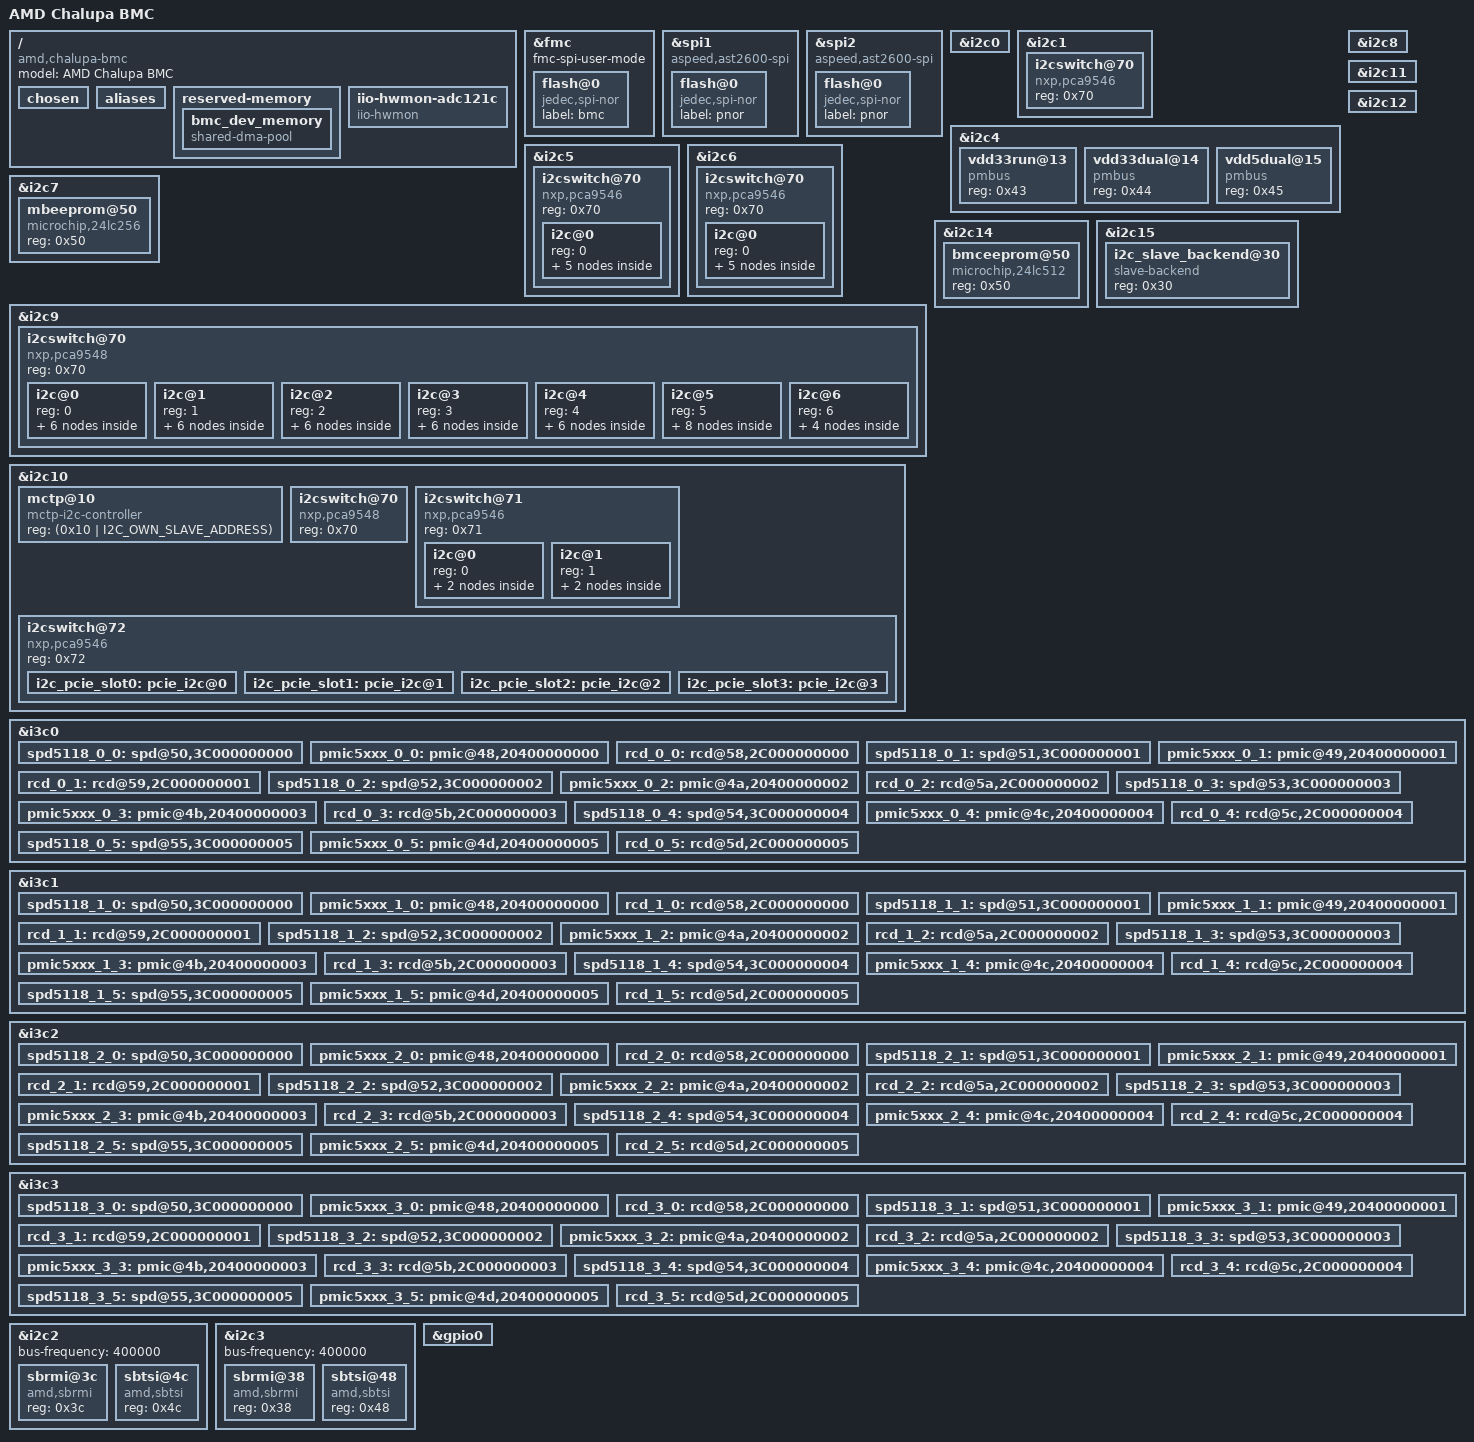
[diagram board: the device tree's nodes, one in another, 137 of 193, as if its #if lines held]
// SPDX-License-Identifier: GPL-2.0
// Copyright (c) 2022 AMD Inc.
// Author: Mohsen Dolaty <mohsen.dolaty@amd.com>
// Author: Supreeth Venkatesh <supreeth.venkatesh@amd.com>

/dts-v1/;
#include "ast2600-amd-bmc-common.dtsi"
#include <dt-bindings/i2c/i2c.h>
#include <dt-bindings/i3c/i3c.h>

/ {
	model = "AMD Chalupa BMC";
	compatible = "amd,chalupa-bmc", "aspeed,ast2600";


	chosen {
		stdout-path = &uart5;
		bootargs = "console=ttyS4,115200 earlycon vmalloc=512MB";
	};
	aliases {
	
		i2c180 = &i2c_pcie_slot0;
		i2c181 = &i2c_pcie_slot1;
		i2c182 = &i2c_pcie_slot2;
		i2c183 = &i2c_pcie_slot3;
	};

	reserved-memory {
		#address-cells = <1>;
		#size-cells = <1>;
		ranges;

        bmc_dev_memory: bmc_dev_memory {
            size = <0x00100000>;
            alignment = <0x00100000>;
            compatible = "shared-dma-pool";
            no-map;
        };
	};

	iio-hwmon-adc121c {
		compatible = "iio-hwmon";
		oemname0 = "FPGA_VDD_CORE";
		oemname1 = "FPGA_VDD_18";
		oemname2 = "FPGA_VDD_33";
		oemname3 = "LOM_VDD_33";
		oemname4 = "LOM_VDD_12";
		oemname5 = "VDD_12_DUAL";
		io-channels = <&adc0 0>, <&adc1 0>, <&adc2 0>, <&adc3 0>,
					<&adc4 0>, <&adc5 0>;
	};
};


&fmc {
	status = "okay";
	fmc-spi-user-mode;
	flash@0 {
		compatible = "jedec,spi-nor";
		status = "okay";
		label = "bmc";
		//spi-tx-bus-width = <4>;
		//spi-rx-bus-width = <4>;
		#include "openbmc-flash-layout-128.dtsi"
	};
};

&spi1 {
	status = "okay";
	pinctrl-names = "default";
	pinctrl-0 = <&pinctrl_spi1_default &pinctrl_qspi1_default>;
	fmc-spi-user-mode;
	compatible = "aspeed,ast2600-spi";

	flash@0 {
		compatible = "jedec,spi-nor";
		label = "pnor";
		status = "okay";
	};

};

&spi2 {
	status = "okay";
	pinctrl-names = "default";
	pinctrl-0 = <&pinctrl_spi2_default &pinctrl_qspi2_default>;
	fmc-spi-user-mode;
	compatible = "aspeed,ast2600-spi";

	flash@0 {
		compatible = "jedec,spi-nor";
		label = "pnor";
		status = "okay";
	};

};

// I2C configs
&i2c0 {
	//Net name i2c9 (SCM_I2C9)- MB FPGA slave
	status = "okay";
};

&i2c1 {
	//Net name i2c12 (SCM_I2C12) - LCD at 50KHz
	// Connected to TCA9546A and to LCD HDR
	status = "okay";
#ifdef OPENBMC_LCD_DRIVER
	i2cswitch@70 {
		compatible = "nxp,pca9546";
		reg = <0x70>;
		//<TBD> Define LCD details here
	};
#endif //OPENBMC_LCD_DRIVER
};

&i2c4 {
	// Net name i2c1 (SCM_I2C1)
	status = "okay";
	vdd33run@13 {
		//VDD_33_RUN VRM
		compatible = "pmbus";
		reg = <0x43>;
	};
	vdd33dual@14 {
		//VDD_33_DUAL VRM
		compatible = "pmbus";
		reg = <0x44>;
	};
	vdd5dual@15 {
		//VDD_5_DUAL VRM
		compatible = "pmbus";
		reg = <0x45>;
	};
};

// BMC Chalupa P0 VRs
&i2c5 {
	// Net name i2c2 (SCM_I2C2)
	status = "okay";

	i2cswitch@70 {
		compatible = "nxp,pca9546";
		reg = <0x70>;
		#address-cells = <1>;
		#size-cells = <0>;

                i2c@0 {
                        #address-cells = <1>;
                        #size-cells = <0>;
                        reg = <0>;

                        p0_vdd_core_0_run@61 {
                                //VDD CORE0 RUN
                                compatible = "isil,isl68137";
                                reg = <0x61>;
                        };

                        p0_vdd_core_1_run@62 {
                                //VDD CORE1 RUN
                                compatible = "isil,isl68137";
                                reg = <0x62>;
                        };

                        p0_vdd_vddio_run@63 {
                                //VDD IO run
                                compatible = "isil,isl68137";
                                reg = <0x63>;
                        };

                        p0_vdd_18_dual@64 {
                                //VDD 18 DUAL
                                compatible = "isil,isl68137";
                                reg = <0x64>;
                        };

                        p0_vdd_33_dual@65 {
                                //VDD 33 DUAL
                                compatible = "isil,isl68137";
                                reg = <0x65>;
                        };
                };
	};
};

// BMC Chalupa P1 VRs
&i2c6 {
	// Net name i2c3 (SCM_I2C3)
	status = "okay";

	i2cswitch@70 {
		compatible = "nxp,pca9546";
		reg = <0x70>;
		#address-cells = <1>;
		#size-cells = <0>;

                i2c@0 {
                        #address-cells = <1>;
                        #size-cells = <0>;
                        reg = <0>;

                        p1_vdd_core0_run@61 {
                                //VDD CORE0 RUN
                                compatible = "isil,isl68137";
                                reg = <0x61>;
                        };

                        p1_vdd_core1_run@62 {
                                //VDD CORE1 RUN
                                compatible = "isil,isl68137";
                                reg = <0x62>;
                        };

                        p1_vdd_vddio_run@63 {
                                //VDD IO RUN
                                compatible = "isil,isl68137";
                                reg = <0x63>;
                        };

                        p1_vdd_18_dual@64 {
                                //VDD 18 DUAL
                                compatible = "isil,isl68137";
                                reg = <0x64>;
                        };

                        p1_vdd_33_dual@65 {
                                //VDD 33 DUAL
                                compatible = "isil,isl68137";
                                reg = <0x65>;
                        };
                };
	};
};

&i2c7 {
	// Net name i2c4 (SCM_I2C4) - HPM BRD ID
	status = "okay";

	mbeeprom@50 {
		compatible = "microchip,24lc256","atmel,24c256";
		reg = <0x50>;
	};
};

&i2c8 {
	// Net name i2c5 (SCM_I2C5) - PSU
	status = "okay";
};

&i2c9 {
	// Net name i2c6 (SCM_I2C6) - FAN/LM75/ADC
	status = "okay";

	i2cswitch@70 {
		compatible = "nxp,pca9548";
		reg = <0x70>;
		#address-cells = <1>;
		#size-cells = <0>;

		//  port 0 to 4 connected to 5 fan controllers which controls 5 fans each
		i2c@0 {
			reg = <0>;
			#address-cells = <1>;
			#size-cells = <0>;

			emc2305@4d {
				compatible = "smsc,emc2305";
				reg = <0x4d>;
				#cooling-cells = <0x02>;

				fan@0 {
					min-rpm = /bits/ 16 <1000>;
					max-rpm = /bits/ 16 <16000>;
				};
				fan@1 {
					min-rpm = /bits/ 16 <1000>;
					max-rpm = /bits/ 16 <16000>;
				};

				fan@2 {
					min-rpm = /bits/ 16 <1000>;
					max-rpm = /bits/ 16 <16000>;
				};

				fan@3 {
					min-rpm = /bits/ 16 <1000>;
					max-rpm = /bits/ 16 <16000>;
				};

				fan@4 {
					min-rpm = /bits/ 16 <1000>;
					max-rpm = /bits/ 16 <16000>;
				};
			};
		};

		i2c@1 {
			reg = <1>;
			#address-cells = <1>;
			#size-cells = <0>;

			emc2305@4d {
				compatible = "smsc,emc2305";
				reg = <0x4d>;
				#cooling-cells = <0x02>;

				fan@0 {
					min-rpm = /bits/ 16 <1000>;
					max-rpm = /bits/ 16 <16000>;
				};
				fan@1 {
					min-rpm = /bits/ 16 <1000>;
					max-rpm = /bits/ 16 <16000>;
				};

				fan@2 {
					min-rpm = /bits/ 16 <1000>;
					max-rpm = /bits/ 16 <16000>;
				};

				fan@3 {
					min-rpm = /bits/ 16 <1000>;
					max-rpm = /bits/ 16 <16000>;
				};

				fan@4 {
					min-rpm = /bits/ 16 <1000>;
					max-rpm = /bits/ 16 <16000>;
				};
			};
		};

		i2c@2 {
			reg = <2>;
			#address-cells = <1>;
			#size-cells = <0>;

			emc2305@4d {
				compatible = "smsc,emc2305";
				reg = <0x4d>;
				#cooling-cells = <0x02>;

				fan@0 {
					min-rpm = /bits/ 16 <1000>;
					max-rpm = /bits/ 16 <16000>;
				};
				fan@1 {
					min-rpm = /bits/ 16 <1000>;
					max-rpm = /bits/ 16 <16000>;
				};

				fan@2 {
					min-rpm = /bits/ 16 <1000>;
					max-rpm = /bits/ 16 <16000>;
				};

				fan@3 {
					min-rpm = /bits/ 16 <1000>;
					max-rpm = /bits/ 16 <16000>;
				};

				fan@4 {
					min-rpm = /bits/ 16 <1000>;
					max-rpm = /bits/ 16 <16000>;
				};
			};
		};

		i2c@3 {
			reg = <3>;
			#address-cells = <1>;
			#size-cells = <0>;

			emc2305@4d {
				compatible = "smsc,emc2305";
				reg = <0x4d>;
				#cooling-cells = <0x02>;

				fan@0 {
					min-rpm = /bits/ 16 <1000>;
					max-rpm = /bits/ 16 <16000>;
				};
				fan@1 {
					min-rpm = /bits/ 16 <1000>;
					max-rpm = /bits/ 16 <16000>;
				};

				fan@2 {
					min-rpm = /bits/ 16 <1000>;
					max-rpm = /bits/ 16 <16000>;
				};

				fan@3 {
					min-rpm = /bits/ 16 <1000>;
					max-rpm = /bits/ 16 <16000>;
				};

				fan@4 {
					min-rpm = /bits/ 16 <1000>;
					max-rpm = /bits/ 16 <16000>;
				};
			};
		};

		i2c@4 {
			reg = <4>;
			#address-cells = <1>;
			#size-cells = <0>;

			emc2305@4d {
				compatible = "smsc,emc2305";
				reg = <0x4d>;
				#cooling-cells = <0x02>;

				fan@0 {
					min-rpm = /bits/ 16 <1000>;
					max-rpm = /bits/ 16 <16000>;
				};
				fan@1 {
					min-rpm = /bits/ 16 <1000>;
					max-rpm = /bits/ 16 <16000>;
				};

				fan@2 {
					min-rpm = /bits/ 16 <1000>;
					max-rpm = /bits/ 16 <16000>;
				};

				fan@3 {
					min-rpm = /bits/ 16 <1000>;
					max-rpm = /bits/ 16 <16000>;
				};

				fan@4 {
					min-rpm = /bits/ 16 <1000>;
					max-rpm = /bits/ 16 <16000>;
				};
			};
		};

		i2c@5 {
			#address-cells = <1>;
			#size-cells = <0>;
			reg = <5>;

			lm75a@48 {
				compatible = "national,lm75a";
				reg = <0x48>;
			};

			lm75a@49 {
				compatible = "national,lm75a";
				reg = <0x49>;
			};

			lm75a@4a {
				compatible = "national,lm75a";
				reg = <0x4a>;
			};

			lm75a@4b {
				compatible = "national,lm75a";
				reg = <0x4b>;
			};

			lm75a@4c {
				compatible = "national,lm75a";
				reg = <0x4c>;
			};

			lm75a@4d {
				compatible = "national,lm75a";
				reg = <0x4d>;
			};

			lm75a@4e {
				compatible = "national,lm75a";
				reg = <0x4e>;
			};

			lm75a@4f {
				compatible = "national,lm75a";
				reg = <0x4f>;
			};
		};

		i2c@6 {
			#address-cells = <1>;
			#size-cells = <0>;
			reg = <6>;

			//adc0: fpga_vdd_core@50 {
			//	compatible = "ti,adc121c";
			//	reg = <0x50>;
			//	#io-channel-cells = <1>;
			//	label = "fpga_vdd_core";
			//};
			//adc1: fpga_vdd_18@51 {
			//	compatible = "ti,adc121c";
			//	reg = <0x51>;
			//	#io-channel-cells = <1>;
			//	label = "fpga_vdd_18";
			//};
			adc2: fpga_vdd_33@52 {
				compatible = "ti,adc121c";
				reg = <0x52>;
				#io-channel-cells = <1>;
				label = "fpga_vdd_33";
			};
			adc3: lom_vdd_33@54 {
				compatible = "ti,adc121c";
				reg = <0x54>;
				#io-channel-cells = <1>;
				label = "lom_vdd_33";
			};
			adc4: lom_vdd_12@55 {
				compatible = "ti,adc121c";
				reg = <0x55>;
				#io-channel-cells = <1>;
				label = "lom_vdd_12";
			};
			adc5: vdd_12_dual@56 {
				compatible = "ti,adc121c";
				reg = <0x56>;
				#io-channel-cells = <1>;
				label = "vdd_12_dual";
			};
		};
	};
};

&i2c10 {
	// Net name i2c7 (SCM_I2C7)
	status = "okay";
	bus-frequency = <400000>;
	multi-master;
	mctp-controller;
	mctp@10 {
		compatible = "mctp-i2c-controller";
		reg = <(0x10 | I2C_OWN_SLAVE_ADDRESS)>;
	};

#ifdef EEPROM_PROG_ENABLE
	i2cswitch@70 {
		compatible = "nxp,pca9548";
		reg = <0x70>;
	};

	i2cswitch@71 {
		compatible = "nxp,pca9546";
		reg = <0x71>;
		#address-cells = <1>;
		#size-cells = <0>;

		i2c@0 {
			#address-cells = <1>;
			#size-cells = <0>;
			reg = <0>;

			p0brdreveeprom@50 {
				//P0 QUARTZ BRD ID
				compatible = "microchip,24lc256","atmel,24c256";
				reg = <0x50>;
			};

			p0scmbrdeeprom@51 {
				//P0 SCM BRD ID
				compatible = "microchip,24lc256","atmel,24c256";
				reg = <0x51>;
			};
		};

		i2c@1 {
			#address-cells = <1>;
			#size-cells = <0>;
			reg = <1>;

			p1brdreveeprom@50 {
				//P1 QUARTZ BRD ID
				compatible = "microchip,24lc256","atmel,24c256";
				reg = <0x50>;
			};

			p2scmbrdeeprom@51 {
				//P1 SCM BRD ID
				compatible = "microchip,24lc256","atmel,24c256";
				reg = <0x51>;
			};
		};
	};

#endif

  // pcie i2c mux
  i2cswitch@72 {
		compatible = "nxp,pca9546";
		reg = <0x72>; // addr of i2c-mux
		#address-cells = <1>; // default 
		#size-cells = <0>;    // default 
		
    i2c_pcie_slot0: pcie_i2c@0 { 
		reg = <0>; #address-cells = <1>; #size-cells = <0>; 
		mctp-controller;
		};
    i2c_pcie_slot1: pcie_i2c@1 { 
		reg = <1>; #address-cells = <1>; #size-cells = <0>; 
		mctp-controller;
		};
    i2c_pcie_slot2: pcie_i2c@2 { 
		reg = <2>; #address-cells = <1>; #size-cells = <0>;
		mctp-controller;
		};
    i2c_pcie_slot3: pcie_i2c@3 { 
		reg = <3>; #address-cells = <1>; #size-cells = <0>; 
		mctp-controller;
		};

  }; //i2cswitch@72 

};


&i2c11 {
	// Net name i2c8 (SCM_I2C8) - MB LOM
	status = "okay";
};

&i2c12 {
	// LOCAL MGMT - FPGA slave
	status = "okay";
};

&i2c14 {
	// LOCAL MGMT - EEPROM, RTC
	status = "okay";
	bmceeprom@50 {
	compatible = "microchip,24lc512","atmel,24c512";
	reg = <0x50>;
	};
};

&i2c15 {
	// RoT
	status = "okay";
	i2c_slave_backend@30 {
		compatible = "slave-backend";
		reg = <0x30>;
	};
};

// i3c

#ifdef ENABLE_I3C_SPD_DIMM
&i3c0 {
	// P0 DIMM (A-F) SPD Access
	status = "okay";
	jdec-spd;
	i2c-scl-hz = <100000>;
	i3c-scl-hz = <2000000>;

	//DIMM A
	spd5118_0_0: spd@50,3C000000000 {
		reg = <0x50 0x3C0 0x00000000>;
		assigned-address = <0x50>;
	};
	pmic5xxx_0_0: pmic@48,20400000000 {
		reg = <0x48 0x204 0x00000000>;
		assigned-address = <0x48>;
	};
	rcd_0_0: rcd@58,2C000000000 {
		reg = <0x58 0x2C0 0x00000000>;
		assigned-address = <0x58>;
	};
	//DIMM B
	spd5118_0_1: spd@51,3C000000001 {
		reg = <0x51 0x3C0 0x00000001>;
		assigned-address = <0x51>;
	};
	pmic5xxx_0_1: pmic@49,20400000001 {
		reg = <0x49 0x204 0x00000001>;
		assigned-address = <0x49>;
	};
	rcd_0_1: rcd@59,2C000000001 {
		reg = <0x59 0x2C0 0x00000001>;
		assigned-address = <0x59>;
	};
	//DIMM C
	spd5118_0_2: spd@52,3C000000002 {
		reg = <0x52 0x3C0 0x00000002>;
		assigned-address = <0x52>;
	};
	pmic5xxx_0_2: pmic@4a,20400000002 {
		reg = <0x4a 0x204 0x00000002>;
		assigned-address = <0x4a>;
	};
	rcd_0_2: rcd@5a,2C000000002 {
		reg = <0x5a 0x2C0 0x00000002>;
		assigned-address = <0x5a>;
	};
	//DIMM D
	spd5118_0_3: spd@53,3C000000003 {
		reg = <0x53 0x3C0 0x00000003>;
		assigned-address = <0x53>;
	};
	pmic5xxx_0_3: pmic@4b,20400000003 {
		reg = <0x4b 0x204 0x00000003>;
		assigned-address = <0x4b>;
	};
	rcd_0_3: rcd@5b,2C000000003 {
		reg = <0x5b 0x2C0 0x00000003>;
		assigned-address = <0x5b>;
	};
	//DIMM E
	spd5118_0_4: spd@54,3C000000004 {
		reg = <0x54 0x3C0 0x00000004>;
		assigned-address = <0x54>;
	};
	pmic5xxx_0_4: pmic@4c,20400000004 {
		reg = <0x4c 0x204 0x00000004>;
		assigned-address = <0x4c>;
	};
	rcd_0_4: rcd@5c,2C000000004 {
		reg = <0x5c 0x2C0 0x00000004>;
		assigned-address = <0x5c>;
	};
	//DIMM F
	spd5118_0_5: spd@55,3C000000005 {
		reg = <0x55 0x3C0 0x00000005>;
		assigned-address = <0x55>;
	};
	pmic5xxx_0_5: pmic@4d,20400000005 {
		reg = <0x4d 0x204 0x00000005>;
		assigned-address = <0x4d>;
	};
	rcd_0_5: rcd@5d,2C000000005 {
		reg = <0x5d 0x2C0 0x00000005>;
		assigned-address = <0x5d>;
	};
};

&i3c1 {
	// P0 DIMM (G-L) SPD Access
	status = "okay";
	jdec-spd;
	i2c-scl-hz = <100000>;
	i3c-scl-hz = <2000000>;

	//DIMM G
	spd5118_1_0: spd@50,3C000000000 {
		reg = <0x50 0x3C0 0x00000000>;
		assigned-address = <0x50>;
	};
	pmic5xxx_1_0: pmic@48,20400000000 {
		reg = <0x48 0x204 0x00000000>;
		assigned-address = <0x48>;
	};
	rcd_1_0: rcd@58,2C000000000 {
		reg = <0x58 0x2C0 0x00000000>;
		assigned-address = <0x58>;
	};
	//DIMM H
	spd5118_1_1: spd@51,3C000000001 {
		reg = <0x51 0x3C0 0x00000001>;
		assigned-address = <0x51>;
	};
	pmic5xxx_1_1: pmic@49,20400000001 {
		reg = <0x49 0x204 0x00000001>;
		assigned-address = <0x49>;
	};
	rcd_1_1: rcd@59,2C000000001 {
		reg = <0x59 0x2C0 0x00000001>;
		assigned-address = <0x59>;
	};
	//DIMM I
	spd5118_1_2: spd@52,3C000000002 {
		reg = <0x52 0x3C0 0x00000002>;
		assigned-address = <0x52>;
	};
	pmic5xxx_1_2: pmic@4a,20400000002 {
		reg = <0x4a 0x204 0x00000002>;
		assigned-address = <0x4a>;
	};
	rcd_1_2: rcd@5a,2C000000002 {
		reg = <0x5a 0x2C0 0x00000002>;
		assigned-address = <0x5a>;
	};
	//DIMM J
	spd5118_1_3: spd@53,3C000000003 {
		reg = <0x53 0x3C0 0x00000003>;
		assigned-address = <0x53>;
	};
	pmic5xxx_1_3: pmic@4b,20400000003 {
		reg = <0x4b 0x204 0x00000003>;
		assigned-address = <0x4b>;
	};
	rcd_1_3: rcd@5b,2C000000003 {
		reg = <0x5b 0x2C0 0x00000003>;
		assigned-address = <0x5b>;
	};
	//DIMM K
	spd5118_1_4: spd@54,3C000000004 {
		reg = <0x54 0x3C0 0x00000004>;
		assigned-address = <0x54>;
	};
	pmic5xxx_1_4: pmic@4c,20400000004 {
		reg = <0x4c 0x204 0x00000004>;
		assigned-address = <0x4c>;
	};
	rcd_1_4: rcd@5c,2C000000004 {
		reg = <0x5c 0x2C0 0x00000004>;
		assigned-address = <0x5c>;
	};
	//DIMM L
	spd5118_1_5: spd@55,3C000000005 {
		reg = <0x55 0x3C0 0x00000005>;
		assigned-address = <0x55>;
	};
	pmic5xxx_1_5: pmic@4d,20400000005 {
		reg = <0x4d 0x204 0x00000005>;
		assigned-address = <0x4d>;
	};
	rcd_1_5: rcd@5d,2C000000005 {
		reg = <0x5d 0x2C0 0x00000005>;
		assigned-address = <0x5d>;
	};
 };

&i3c2 {
	// P1 DIMM (A-F) SPD Access
	status = "okay";
	jdec-spd;
	i2c-scl-hz = <100000>;
	i3c-scl-hz = <2000000>;
	pinctrl-names = "default";
	pinctrl-0 = <&pinctrl_i3c3_default>;

	//DIMM A
	spd5118_2_0: spd@50,3C000000000 {
		reg = <0x50 0x3C0 0x00000000>;
		assigned-address = <0x50>;
	};
	pmic5xxx_2_0: pmic@48,20400000000 {
		reg = <0x48 0x204 0x00000000>;
		assigned-address = <0x48>;
	};
	rcd_2_0: rcd@58,2C000000000 {
		reg = <0x58 0x2C0 0x00000000>;
		assigned-address = <0x58>;
	};
	//DIMM B
	spd5118_2_1: spd@51,3C000000001 {
		reg = <0x51 0x3C0 0x00000001>;
		assigned-address = <0x51>;
	};
	pmic5xxx_2_1: pmic@49,20400000001 {
		reg = <0x49 0x204 0x00000001>;
		assigned-address = <0x49>;
	};
	rcd_2_1: rcd@59,2C000000001 {
		reg = <0x59 0x2C0 0x00000001>;
		assigned-address = <0x59>;
	};
	//DIMM C
	spd5118_2_2: spd@52,3C000000002 {
		reg = <0x52 0x3C0 0x00000002>;
		assigned-address = <0x52>;
	};
	pmic5xxx_2_2: pmic@4a,20400000002 {
		reg = <0x4a 0x204 0x00000002>;
		assigned-address = <0x4a>;
	};
	rcd_2_2: rcd@5a,2C000000002 {
		reg = <0x5a 0x2C0 0x00000002>;
		assigned-address = <0x5a>;
	};
	//DIMM D
	spd5118_2_3: spd@53,3C000000003 {
		reg = <0x53 0x3C0 0x00000003>;
		assigned-address = <0x53>;
	};
	pmic5xxx_2_3: pmic@4b,20400000003 {
		reg = <0x4b 0x204 0x00000003>;
		assigned-address = <0x4b>;
	};
	rcd_2_3: rcd@5b,2C000000003 {
		reg = <0x5b 0x2C0 0x00000003>;
		assigned-address = <0x5b>;
	};
	//DIMM E
	spd5118_2_4: spd@54,3C000000004 {
		reg = <0x54 0x3C0 0x00000004>;
		assigned-address = <0x54>;
	};
	pmic5xxx_2_4: pmic@4c,20400000004 {
		reg = <0x4c 0x204 0x00000004>;
		assigned-address = <0x4c>;
	};
	rcd_2_4: rcd@5c,2C000000004 {
		reg = <0x5c 0x2C0 0x00000004>;
		assigned-address = <0x5c>;
	};
	//DIMM F
	spd5118_2_5: spd@55,3C000000005 {
		reg = <0x55 0x3C0 0x00000005>;
		assigned-address = <0x55>;
	};
	pmic5xxx_2_5: pmic@4d,20400000005 {
		reg = <0x4d 0x204 0x00000005>;
		assigned-address = <0x4d>;
	};
	rcd_2_5: rcd@5d,2C000000005 {
		reg = <0x5d 0x2C0 0x00000005>;
		assigned-address = <0x5d>;
	};
};

&i3c3 {
	// P1 DIMM (G-L) SPD Access
	status = "okay";
	jdec-spd;
	i2c-scl-hz = <100000>;
	i3c-scl-hz = <2000000>;
	pinctrl-names = "default";
	pinctrl-0 = <&pinctrl_i3c4_default>;

	//DIMM G
	spd5118_3_0: spd@50,3C000000000 {
		reg = <0x50 0x3C0 0x00000000>;
		assigned-address = <0x50>;
	};
	pmic5xxx_3_0: pmic@48,20400000000 {
		reg = <0x48 0x204 0x00000000>;
		assigned-address = <0x48>;
	};
	rcd_3_0: rcd@58,2C000000000 {
		reg = <0x58 0x2C0 0x00000000>;
		assigned-address = <0x58>;
	};
	//DIMM H
	spd5118_3_1: spd@51,3C000000001 {
		reg = <0x51 0x3C0 0x00000001>;
		assigned-address = <0x51>;
	};
	pmic5xxx_3_1: pmic@49,20400000001 {
		reg = <0x49 0x204 0x00000001>;
		assigned-address = <0x49>;
	};
	rcd_3_1: rcd@59,2C000000001 {
		reg = <0x59 0x2C0 0x00000001>;
		assigned-address = <0x59>;
	};
	//DIMM I
	spd5118_3_2: spd@52,3C000000002 {
		reg = <0x52 0x3C0 0x00000002>;
		assigned-address = <0x52>;
	};
	pmic5xxx_3_2: pmic@4a,20400000002 {
		reg = <0x4a 0x204 0x00000002>;
		assigned-address = <0x4a>;
	};
	rcd_3_2: rcd@5a,2C000000002 {
		reg = <0x5a 0x2C0 0x00000002>;
		assigned-address = <0x5a>;
	};
	//DIMM J
	spd5118_3_3: spd@53,3C000000003 {
		reg = <0x53 0x3C0 0x00000003>;
		assigned-address = <0x53>;
	};
	pmic5xxx_3_3: pmic@4b,20400000003 {
		reg = <0x4b 0x204 0x00000003>;
		assigned-address = <0x4b>;
	};
	rcd_3_3: rcd@5b,2C000000003 {
		reg = <0x5b 0x2C0 0x00000003>;
		assigned-address = <0x5b>;
	};
	//DIMM K
	spd5118_3_4: spd@54,3C000000004 {
		reg = <0x54 0x3C0 0x00000004>;
		assigned-address = <0x54>;
	};
	pmic5xxx_3_4: pmic@4c,20400000004 {
		reg = <0x4c 0x204 0x00000004>;
		assigned-address = <0x4c>;
	};
	rcd_3_4: rcd@5c,2C000000004 {
		reg = <0x5c 0x2C0 0x00000004>;
		assigned-address = <0x5c>;
	};
	//DIMM L
	spd5118_3_5: spd@55,3C000000005 {
		reg = <0x55 0x3C0 0x00000005>;
		assigned-address = <0x55>;
	};
	pmic5xxx_3_5: pmic@4d,20400000005 {
		reg = <0x4d 0x204 0x00000005>;
		assigned-address = <0x4d>;
	};
	rcd_3_5: rcd@5d,2C000000005 {
		reg = <0x5d 0x2C0 0x00000005>;
		assigned-address = <0x5d>;
	};
};

#else // #ifdef ENABLE_I3C_SPD_DIMM

#define JESD300_SPD_I2C_MODE(bus, index, addr) \
spd_ ## bus ## _ ## index: spd@addr { \
	compatible = "eeprom"; \
	reg = <0x ## addr 0x0 0x0>; \
}

#define JESD300_PMIC_I2C_MODE(bus, index, addr) \
pmic5xxx_ ## bus ## _ ## index: pmic@addr { \
	compatible = "eeprom"; \
	reg = <0x ## addr 0x0 0x0>; \
}

#define JESD300_RCD_I2C_MODE(bus, index, addr) \
rcd_ ## bus ## _ ## index: rcd@addr { \
	compatible = "eeprom"; \
	reg = <0x ## addr 0x0 0x0>; \
}

&i3c0 {
	// P0 DIMM (A-F) SPD Access
	status = "okay";
	jdec-spd;
	i2c-scl-hz = <100000>;

	// DIMM A
	JESD300_SPD_I2C_MODE(0, 0, 50);
	JESD300_PMIC_I2C_MODE(0, 0, 48);
	JESD300_RCD_I2C_MODE(0, 0, 58);

	// DIMM B
	JESD300_SPD_I2C_MODE(0, 1, 51);
	JESD300_PMIC_I2C_MODE(0, 1, 49);
	JESD300_RCD_I2C_MODE(0, 1, 59);

	// DIMM C
	JESD300_SPD_I2C_MODE(0, 2, 52);
	JESD300_PMIC_I2C_MODE(0, 2, 4A);
	JESD300_RCD_I2C_MODE(0, 2, 5A);

	// DIMM D
	JESD300_SPD_I2C_MODE(0, 3, 53);
	JESD300_PMIC_I2C_MODE(0, 3, 4B);
	JESD300_RCD_I2C_MODE(0, 3, 5B);

	// DIMM E
	JESD300_SPD_I2C_MODE(0, 4, 54);
	JESD300_PMIC_I2C_MODE(0, 4, 4C);
	JESD300_RCD_I2C_MODE(0, 4, 5C);

	// DIMM F
	JESD300_SPD_I2C_MODE(0, 5, 55);
	JESD300_PMIC_I2C_MODE(0, 5, 4D);
	JESD300_RCD_I2C_MODE(0, 5, 5D);
};

&i3c1 {
	// P0 DIMM (G-L) SPD Access
	status = "okay";
	jdec-spd;
	i2c-scl-hz = <100000>;

	// DIMM G
	JESD300_SPD_I2C_MODE(1, 0, 50);
	JESD300_PMIC_I2C_MODE(1, 0, 48);
	JESD300_RCD_I2C_MODE(1, 0, 58);

	// DIMM H
	JESD300_SPD_I2C_MODE(1, 1, 51);
	JESD300_PMIC_I2C_MODE(1, 1, 49);
	JESD300_RCD_I2C_MODE(1, 1, 59);

	// DIMM I
	JESD300_SPD_I2C_MODE(1, 2, 52);
	JESD300_PMIC_I2C_MODE(1, 2, 4A);
	JESD300_RCD_I2C_MODE(1, 2, 5A);

	// DIMM J
	JESD300_SPD_I2C_MODE(1, 3, 53);
	JESD300_PMIC_I2C_MODE(1, 3, 4B);
	JESD300_RCD_I2C_MODE(1, 3, 5B);

	// DIMM K
	JESD300_SPD_I2C_MODE(1, 4, 54);
	JESD300_PMIC_I2C_MODE(1, 4, 4C);
	JESD300_RCD_I2C_MODE(1, 4, 5C);

	// DIMM L
	JESD300_SPD_I2C_MODE(1, 5, 55);
	JESD300_PMIC_I2C_MODE(1, 5, 4D);
	JESD300_RCD_I2C_MODE(1, 5, 5D);
};

&i3c2 {
	// P1 DIMM (A-F) SPD Access
	status = "okay";
	jdec-spd;
	i2c-scl-hz = <100000>;
	pinctrl-names = "default";
	pinctrl-0 = <&pinctrl_i3c3_default>;

	// DIMM A
	JESD300_SPD_I2C_MODE(2, 0, 50);
	JESD300_PMIC_I2C_MODE(2, 0, 48);
	JESD300_RCD_I2C_MODE(2, 0, 58);

	// DIMM B
	JESD300_SPD_I2C_MODE(2, 1, 51);
	JESD300_PMIC_I2C_MODE(2, 1, 49);
	JESD300_RCD_I2C_MODE(2, 1, 59);

	// DIMM C
	JESD300_SPD_I2C_MODE(2, 2, 52);
	JESD300_PMIC_I2C_MODE(2, 2, 4A);
	JESD300_RCD_I2C_MODE(2, 2, 5A);

	// DIMM D
	JESD300_SPD_I2C_MODE(2, 3, 53);
	JESD300_PMIC_I2C_MODE(2, 3, 4B);
	JESD300_RCD_I2C_MODE(2, 3, 5B);

	// DIMM E
	JESD300_SPD_I2C_MODE(2, 4, 54);
	JESD300_PMIC_I2C_MODE(2, 4, 4C);
	JESD300_RCD_I2C_MODE(2, 4, 5C);

	// DIMM F
	JESD300_SPD_I2C_MODE(2, 5, 55);
	JESD300_PMIC_I2C_MODE(2, 5, 4D);
	JESD300_RCD_I2C_MODE(2, 5, 5D);
};

&i3c3 {
	// P1 DIMM (G-L) SPD Access
	status = "okay";
	jdec-spd;
	i2c-scl-hz = <100000>;
	pinctrl-names = "default";
	pinctrl-0 = <&pinctrl_i3c4_default>;

	// DIMM G
	JESD300_SPD_I2C_MODE(3, 0, 50);
	JESD300_PMIC_I2C_MODE(3, 0, 48);
	JESD300_RCD_I2C_MODE(3, 0, 58);

	// DIMM H
	JESD300_SPD_I2C_MODE(3, 1, 51);
	JESD300_PMIC_I2C_MODE(3, 1, 49);
	JESD300_RCD_I2C_MODE(3, 1, 59);

	// DIMM I
	JESD300_SPD_I2C_MODE(3, 2, 52);
	JESD300_PMIC_I2C_MODE(3, 2, 4A);
	JESD300_RCD_I2C_MODE(3, 2, 5A);

	// DIMM J
	JESD300_SPD_I2C_MODE(3, 3, 53);
	JESD300_PMIC_I2C_MODE(3, 3, 4B);
	JESD300_RCD_I2C_MODE(3, 3, 5B);

	// DIMM K
	JESD300_SPD_I2C_MODE(3, 4, 54);
	JESD300_PMIC_I2C_MODE(3, 4, 4C);
	JESD300_RCD_I2C_MODE(3, 4, 5C);

	// DIMM L
	JESD300_SPD_I2C_MODE(3, 5, 55);
	JESD300_PMIC_I2C_MODE(3, 5, 4D);
	JESD300_RCD_I2C_MODE(3, 5, 5D);
};
#endif // #ifdef ENABLE_I3C_SPD_DIMM

&i2c2 {
	// P0 APML - i2c10
	status = "okay";
	bus-frequency = <400000>;

	sbrmi@3c {
		compatible = "amd,sbrmi";
		reg = <0x3c>;
	};

	sbtsi@4c {
		compatible = "amd,sbtsi";
		reg = <0x4c>;
	};
};

&i2c3 {
	// P1 APML - i2c11
	status = "okay";
	bus-frequency = <400000>;

	sbrmi@38 {
		compatible = "amd,sbrmi";
		reg = <0x38>;
	};

	sbtsi@48 {
		compatible = "amd,sbtsi";
		reg = <0x48>;
	};
};


&gpio0 {
	gpio-line-names =
	/*A0-A7*/	"","","","","","","","",
	/*B0-B7*/	"","","","","MON_POST_COMPLETE","P0_PRESENT_L","","P1_PRESENT_L",
	/*C0-C7*/	"","","","","","","","",
	/*D0-D7*/	"","","","","","","","",
	/*E0-E7*/	"","","","","","","","",
	/*F0-F7*/	"","","","","","","","",
	/*G0-G7*/	"","","","","","","","MON_RSMRST_L",
	/*H0-H7*/	"","ASSERT_WARM_RST_BTN_L","ASSERT_SOC_RST_BTN_L","","","","","",
	/*I0-I7*/	"","","","","","","","P0_I3C_APML_ALERT_L",
	/*J0-J7*/	"","","","","","","","",
	/*K0-K7*/	"","","","","","","","",
	/*L0-L7*/	"","","","","","","","",
	/*M0-M7*/	"","","","","","","","",
	/*N0-N7*/	"","","P0_THERMTRIP_L","P1_THERMTRIP_L","","","PSP_SOFT_FUSE_NOTIFY","ASSERT_BMC_READY",
	/*O0-O7*/	"","","HDT_SEL","HDT_XTRIG5","HDT_XTRIG6","JTAG_TRST_N","","",
	/*P0-P7*/	"MON_RST_BTN_L","ASSERT_RST_BTN_L","MON_PWR_BTN_L","ASSERT_PWR_BTN_L","","ASSERT_NMI_BTN_L","MON_PWR_GOOD","",
	/*Q0-Q7*/	"","","HDT_DBREQ_L","","BIOS_SPD_MUX_CTRL_RELEASED_L","","","",
	/*R0-R7*/	"","","","","","","","",
	/*S0-S7*/	"","","","","P1_DIMM_AF_ERROR","P1_DIMM_GL_ERROR","P0_DIMM_AF_ERROR","P0_DIMM_GL_ERROR",
	/*T0-T7*/	"","","","","","","","",
	/*U0-U7*/	"","","","","P1_I3C_APML_ALERT_L","","","",
	/*V0-V7*/	"","","","RSMRST","","","","",
	/*W0-W7*/	"","","","","","","","",
	/*X0-X7*/	"","","","","","","","",
	/*Y0-Y7*/	"","","","","","","","",
	/*Z0-Z7*/	"","","","","","","","";
};


